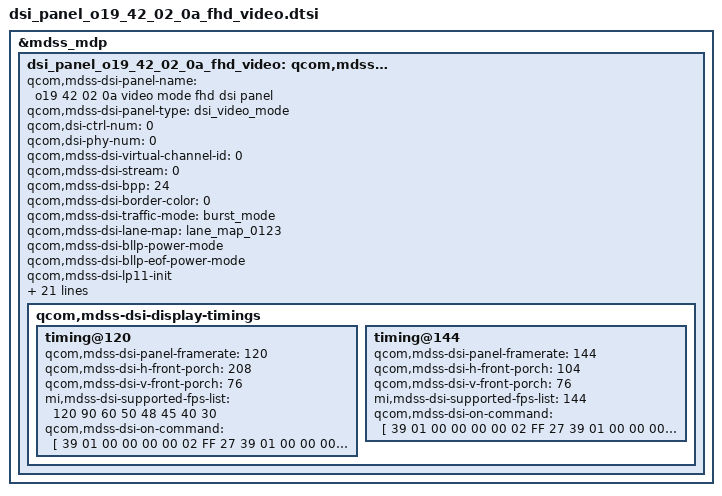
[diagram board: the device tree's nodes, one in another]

&mdss_mdp {
	dsi_panel_o19_42_02_0a_fhd_video: qcom,mdss_dsi_panel_o19_42_02_0a_fhd_video {
		qcom,mdss-dsi-panel-name =
			"o19 42 02 0a video mode fhd dsi panel";
		qcom,mdss-dsi-panel-type = "dsi_video_mode";
		qcom,dsi-ctrl-num = <0>;
		qcom,dsi-phy-num = <0>;
		qcom,mdss-dsi-virtual-channel-id = <0>;
		qcom,mdss-dsi-stream = <0>;
		qcom,mdss-dsi-bpp = <24>;
		qcom,mdss-dsi-border-color = <0>;
		qcom,mdss-dsi-traffic-mode = "burst_mode";
		qcom,mdss-dsi-lane-map = "lane_map_0123";
		qcom,mdss-dsi-bllp-power-mode;
		qcom,mdss-dsi-bllp-eof-power-mode;
		qcom,mdss-dsi-lp11-init;
		qcom,mdss-dsi-lane-0-state;
		qcom,mdss-dsi-lane-1-state;
		qcom,mdss-dsi-lane-2-state;
		qcom,mdss-dsi-lane-3-state;
		qcom,mdss-dsi-dma-trigger = "trigger_sw";
		qcom,mdss-dsi-mdp-trigger = "none";
		qcom,mdss-dsi-bl-inverted-dbv;
		qcom,mdss-dsi-bl-lcd-number = <1>;
		qcom,mdss-dsi-reset-sequence = <0 10>, <1 10>, <0 10>, <1 10>;
		qcom,mdss-dsi-tx-eot-append;
		qcom,adjust-timer-wakeup-ms = <1>;
		qcom,mdss-brightness-init-level = <307>;
		qcom,mdss-pan-physical-width-dimension = <74>;
		qcom,mdss-pan-physical-height-dimension = <159>;
		qcom,mdss-dsi-pan-enable-dynamic-fps;
		qcom,mdss-dsi-pan-fps-update = "dfps_immediate_porch_mode_vfp";
		qcom,dsi-supported-dfps-list = <120 144 90 60 50 48 45 40 30>;
		mi,video-mode-multi-timing;
		qcom,mdss-dsi-display-timings {
			timing@120 {
				qcom,mdss-dsi-panel-framerate = <120>;
				qcom,mdss-dsi-h-front-porch = <208>;
				qcom,mdss-dsi-v-front-porch = <76>;
				mi,mdss-dsi-supported-fps-list = <120 90 60 50 48 45 40 30>;
				qcom,mdss-dsi-on-command = [
					39 01 00 00 00 00 02 FF 27
					39 01 00 00 00 00 02 FB 01
					39 01 00 00 00 00 02 3F 01
					39 01 00 00 00 00 02 40 55//FTE1_SEL=5=>ESD detection signal
					39 01 00 00 00 00 02 43 18

					39 01 00 00 00 00 02 FF 23
					39 01 00 00 00 00 02 FB 01
					39 01 00 00 00 00 02 00 60
					39 01 00 00 00 00 02 01 84
					39 01 00 00 00 00 02 07 20
					39 01 00 00 00 00 02 08 01
					39 01 00 00 00 00 02 09 55
					39 01 00 00 00 00 02 0A B8
					39 01 00 00 00 00 02 0B B8
					39 01 00 00 00 00 02 0C 7F
					39 01 00 00 00 00 02 0D 00
					//Based on Resolution
					39 01 00 00 00 00 02 11 01
					39 01 00 00 00 00 02 12 BA
					39 01 00 00 00 00 02 15 D4
					39 01 00 00 00 00 02 16 0C

					39 01 00 00 00 00 02 19 07
					39 01 00 00 00 00 02 1A 07
					39 01 00 00 00 00 02 1B 10
					39 01 00 00 00 00 02 1C 12
					39 01 00 00 00 00 02 1D 14
					39 01 00 00 00 00 02 1E 16
					39 01 00 00 00 00 02 1F 18
					39 01 00 00 00 00 02 20 1A
					39 01 00 00 00 00 02 21 21
					39 01 00 00 00 00 02 22 21
					39 01 00 00 00 00 02 23 26
					39 01 00 00 00 00 02 24 2B
					39 01 00 00 00 00 02 25 31
					39 01 00 00 00 00 02 26 35
					39 01 00 00 00 00 02 27 39
					39 01 00 00 00 00 02 28 3C
					39 01 00 00 00 00 02 29 0F
					39 01 00 00 00 00 02 2A 3F
					39 01 00 00 00 00 02 2B 3F

					39 01 00 00 00 00 02 30 FF
					39 01 00 00 00 00 02 31 FD
					39 01 00 00 00 00 02 32 FB
					39 01 00 00 00 00 02 33 F9
					39 01 00 00 00 00 02 34 F7
					39 01 00 00 00 00 02 35 F5
					39 01 00 00 00 00 02 36 F3
					39 01 00 00 00 00 02 37 F1
					39 01 00 00 00 00 02 38 EF
					39 01 00 00 00 00 02 39 ED
					39 01 00 00 00 00 02 3A EB
					39 01 00 00 00 00 02 3B E9
					39 01 00 00 00 00 02 3D E7
					39 01 00 00 00 00 02 3F E5
					39 01 00 00 00 00 02 40 E5
					39 01 00 00 00 00 02 41 E5

					39 01 00 00 00 00 02 45 FF
					39 01 00 00 00 00 02 46 FD
					39 01 00 00 00 00 02 47 F6
					39 01 00 00 00 00 02 48 F0
					39 01 00 00 00 00 02 49 EA
					39 01 00 00 00 00 02 4A E5
					39 01 00 00 00 00 02 4B E0
					39 01 00 00 00 00 02 4C DB
					39 01 00 00 00 00 02 4D D6
					39 01 00 00 00 00 02 4E D0
					39 01 00 00 00 00 02 4F CA
					39 01 00 00 00 00 02 50 C4
					39 01 00 00 00 00 02 51 BE
					39 01 00 00 00 00 02 52 B9
					39 01 00 00 00 00 02 53 B5
					39 01 00 00 00 00 02 54 66

					39 01 00 00 00 00 02 58 FF
					39 01 00 00 00 00 02 59 FD
					39 01 00 00 00 00 02 5A F6
					39 01 00 00 00 00 02 5B F0
					39 01 00 00 00 00 02 5C EA
					39 01 00 00 00 00 02 5D E2
					39 01 00 00 00 00 02 5E E0
					39 01 00 00 00 00 02 5F DB
					39 01 00 00 00 00 02 60 D6
					39 01 00 00 00 00 02 61 D0
					39 01 00 00 00 00 02 62 CA
					39 01 00 00 00 00 02 63 C4
					39 01 00 00 00 00 02 64 BE
					39 01 00 00 00 00 02 65 B9
					39 01 00 00 00 00 02 66 B5
					39 01 00 00 00 00 02 67 B2

					39 01 00 00 00 00 02 FF 23
					39 01 00 00 00 00 02 FB 01
					39 01 00 00 00 00 02 00 60
					39 01 00 00 00 00 02 07 20
					39 01 00 00 00 00 02 08 01
					39 01 00 00 00 00 02 09 55

					//39 01 00 00 00 00 02 FF 2B
					//39 01 00 00 00 00 02 FB 01
					//39 01 00 00 00 00 02 B7 4B
					//39 01 00 00 00 00 02 B8 04
					//39 01 00 00 00 00 02 C0 05

					39 01 00 00 00 00 02 FF 25
					39 01 00 00 00 00 02 FB 01
					39 01 00 00 00 00 02 18 21

					39 01 00 00 00 00 02 FF F0
					39 01 00 00 00 00 02 FB 01
					39 01 00 00 00 00 02 27 09

					39 01 00 00 00 00 02 FF 2A
					39 01 00 00 00 00 02 FB 01
					39 01 00 00 00 00 02 1A 30

					39 01 00 00 00 00 02 FF 10
					39 01 00 00 00 00 02 FB 01
					39 01 00 00 00 00 02 B0 00
					39 01 00 00 00 00 11 C1 89 28 00 14 02 00 02 0E 01 E8 00 07 05 0E 05 16
					39 01 00 00 00 00 03 C2 10 F0
					39 01 00 00 00 00 02 E9 01

					39 01 00 00 00 00 02 FF 10
					39 01 00 00 00 00 02 FB 01
					39 01 00 00 00 00 02 35 00
					39 01 00 00 00 00 02 53 2C
					39 01 00 00 00 00 02 55 00
					39 01 00 00 00 00 03 68 02 01

					05 01 00 00 78 00 01 11
					05 01 00 00 05 00 01 29
				];

				#include "dsi_panel_o19_42_02_0a_fhd_video_common.dtsi"
			};
			timing@144 {
				qcom,mdss-dsi-panel-framerate = <144>;
				qcom,mdss-dsi-h-front-porch = <104>;
				qcom,mdss-dsi-v-front-porch = <76>;
				mi,mdss-dsi-supported-fps-list = <144>;
				qcom,mdss-dsi-on-command = [
					39 01 00 00 00 00 02 FF 27
					39 01 00 00 00 00 02 FB 01
					39 01 00 00 00 00 02 3F 01
					39 01 00 00 00 00 02 40 55//FTE1_SEL=5=>ESD detection signal
					39 01 00 00 00 00 02 43 18

					39 01 00 00 00 00 02 FF 23
					39 01 00 00 00 00 02 FB 01
					39 01 00 00 00 00 02 00 60
					39 01 00 00 00 00 02 01 84
					39 01 00 00 00 00 02 07 20
					39 01 00 00 00 00 02 08 01
					39 01 00 00 00 00 02 09 55
					39 01 00 00 00 00 02 0A B8
					39 01 00 00 00 00 02 0B B8
					39 01 00 00 00 00 02 0C 7F
					39 01 00 00 00 00 02 0D 00
					//Based on Resolution
					39 01 00 00 00 00 02 11 01
					39 01 00 00 00 00 02 12 BA
					39 01 00 00 00 00 02 15 D4
					39 01 00 00 00 00 02 16 0C

					39 01 00 00 00 00 02 19 07
					39 01 00 00 00 00 02 1A 07
					39 01 00 00 00 00 02 1B 10
					39 01 00 00 00 00 02 1C 12
					39 01 00 00 00 00 02 1D 14
					39 01 00 00 00 00 02 1E 16
					39 01 00 00 00 00 02 1F 18
					39 01 00 00 00 00 02 20 1A
					39 01 00 00 00 00 02 21 21
					39 01 00 00 00 00 02 22 21
					39 01 00 00 00 00 02 23 26
					39 01 00 00 00 00 02 24 2B
					39 01 00 00 00 00 02 25 31
					39 01 00 00 00 00 02 26 35
					39 01 00 00 00 00 02 27 39
					39 01 00 00 00 00 02 28 3C
					39 01 00 00 00 00 02 29 0F
					39 01 00 00 00 00 02 2A 3F
					39 01 00 00 00 00 02 2B 3F

					39 01 00 00 00 00 02 30 FF
					39 01 00 00 00 00 02 31 FD
					39 01 00 00 00 00 02 32 FB
					39 01 00 00 00 00 02 33 F9
					39 01 00 00 00 00 02 34 F7
					39 01 00 00 00 00 02 35 F5
					39 01 00 00 00 00 02 36 F3
					39 01 00 00 00 00 02 37 F1
					39 01 00 00 00 00 02 38 EF
					39 01 00 00 00 00 02 39 ED
					39 01 00 00 00 00 02 3A EB
					39 01 00 00 00 00 02 3B E9
					39 01 00 00 00 00 02 3D E7
					39 01 00 00 00 00 02 3F E5
					39 01 00 00 00 00 02 40 E5
					39 01 00 00 00 00 02 41 E5

					39 01 00 00 00 00 02 45 FF
					39 01 00 00 00 00 02 46 FD
					39 01 00 00 00 00 02 47 F6
					39 01 00 00 00 00 02 48 F0
					39 01 00 00 00 00 02 49 EA
					39 01 00 00 00 00 02 4A E5
					39 01 00 00 00 00 02 4B E0
					39 01 00 00 00 00 02 4C DB
					39 01 00 00 00 00 02 4D D6
					39 01 00 00 00 00 02 4E D0
					39 01 00 00 00 00 02 4F CA
					39 01 00 00 00 00 02 50 C4
					39 01 00 00 00 00 02 51 BE
					39 01 00 00 00 00 02 52 B9
					39 01 00 00 00 00 02 53 B5
					39 01 00 00 00 00 02 54 66

					39 01 00 00 00 00 02 58 FF
					39 01 00 00 00 00 02 59 FD
					39 01 00 00 00 00 02 5A F6
					39 01 00 00 00 00 02 5B F0
					39 01 00 00 00 00 02 5C EA
					39 01 00 00 00 00 02 5D E2
					39 01 00 00 00 00 02 5E E0
					39 01 00 00 00 00 02 5F DB
					39 01 00 00 00 00 02 60 D6
					39 01 00 00 00 00 02 61 D0
					39 01 00 00 00 00 02 62 CA
					39 01 00 00 00 00 02 63 C4
					39 01 00 00 00 00 02 64 BE
					39 01 00 00 00 00 02 65 B9
					39 01 00 00 00 00 02 66 B5
					39 01 00 00 00 00 02 67 B2

					39 01 00 00 00 00 02 FF 23
					39 01 00 00 00 00 02 FB 01
					39 01 00 00 00 00 02 00 60
					39 01 00 00 00 00 02 07 20
					39 01 00 00 00 00 02 08 01
					39 01 00 00 00 00 02 09 55

					//39 01 00 00 00 00 02 FF 2B
					//39 01 00 00 00 00 02 FB 01
					//39 01 00 00 00 00 02 B7 4B
					//39 01 00 00 00 00 02 B8 04
					//39 01 00 00 00 00 02 C0 05

					39 01 00 00 00 00 02 FF 25
					39 01 00 00 00 00 02 FB 01
					39 01 00 00 00 00 02 18 20

					39 01 00 00 00 00 02 FF F0
					39 01 00 00 00 00 02 FB 01
					39 01 00 00 00 00 02 27 09

					39 01 00 00 00 00 02 FF 2A
					39 01 00 00 00 00 02 FB 01
					39 01 00 00 00 00 02 1A 30

					39 01 00 00 00 00 02 FF 10
					39 01 00 00 00 00 02 FB 01
					39 01 00 00 00 00 02 B0 00
					39 01 00 00 00 00 11 C1 89 28 00 14 02 00 02 0E 01 E8 00 07 05 0E 05 16
					39 01 00 00 00 00 03 C2 10 F0
					39 01 00 00 00 00 02 E9 01

					39 01 00 00 00 00 02 FF 10
					39 01 00 00 00 00 02 FB 01
					39 01 00 00 00 00 02 35 00
					39 01 00 00 00 00 02 53 2C
					39 01 00 00 00 00 02 55 00
					39 01 00 00 00 00 03 68 02 01

					05 01 00 00 78 00 01 11
					05 01 00 00 05 00 01 29
				];

				#include "dsi_panel_o19_42_02_0a_fhd_video_common.dtsi"
			};
		};
	};
};
